AUTOSAR XML (schema 4-0-3)
standard types defined: uint8, Boolean
package /AUTOSAR_Platform/DataConstrs
  range DC_Boolean: raw 0..1
package /DataTypes/Units
  unit NoUnit1: display-name=NoUnit, factor-si-to-unit=1, offset-si-to-unit=0
package /PATAC/MSM/ComponentTypes
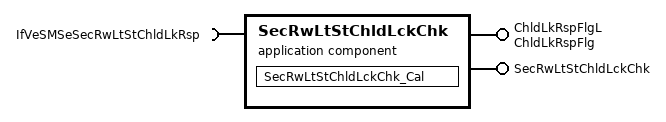
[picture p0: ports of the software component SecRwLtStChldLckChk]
  application sw component type SecRwLtStChldLckChk
    provide port ChldLkRspFlgL: nonqueued-sender-com-spec{data-element=ChldLkRspFlg/Val, init-value=0}, provided-interface=ChldLkRspFlg
    provide port SecRwLtStChldLckChk: server-com-spec{operation=Cal, queue-length=1}, provided-interface=SecRwLtStChldLckChk
    require port IfVeSMSeSecRwLtStChldLkRsp: nonqueued-receiver-com-spec{data-element=IfVeSMSeSecRwLtStChldLkRsp/Val, filter=data-filter-type=ALWAYS, init-value=0}, required-interface=IfVeSMSeSecRwLtStChldLkRsp
    behavior SecRwLtStChldLckChk_InternalBehavior
      operation invoked event OIT_SecRwLtStChldLckChk_Cal_SecRwLtStChldLckChk_Cal: start-on-event=SecRwLtStChldLckChk_Cal, operation=SecRwLtStChldLckChk.Cal
      runnable SecRwLtStChldLckChk_Cal
        data-receive-point-by-arguments:
          access REC_IfVeSMSeSecRwLtStChldLkRsp_Val: accessed-variable=IfVeSMSeSecRwLtStChldLkRsp.Val
        data-send-points:
          access SEND_ChldLkRspFlgL_Val: accessed-variable=ChldLkRspFlgL.Val
  swc implementation SecRwLtStChldLckChk_Implementation: behavior=SecRwLtStChldLckChk_InternalBehavior
    code-descriptors:
      code Default: artifact-descriptors=autosar-engineering-object={short-label=Default, category=SWSRC}
package /PATAC/MSM/DataTypes
  impl type SeatChldLkSt: category=VALUE, base-type=uint8, compu {0=ChldLkSt_NoActive, 1=ChldLkSt_Lock, 2=ChldLkSt_Unlock}
package /PATAC/MSM/ModeAdjust/Interfaces
  sender receiver interface IfVeSMSeSecRwLtStChldLkRsp: invalidation-policy{data-element=IfVeSMSeSecRwLtStChldLkRsp/Val, handle-invalid=DONT-INVALIDATE}
    data Val: type=SeatChldLkSt
package /PATAC/MSM/ModeAdjust/PortInterface
  client server interface SecRwLtStChldLckChk
    operation Cal
  sender receiver interface ChldLkRspFlg: invalidation-policy{data-element=ChldLkRspFlg/Val, handle-invalid=DONT-INVALIDATE}
    data Val: type=Boolean
